# STM32G431 register map
File version: 2.8
CPU: CM4 r0p1, little endian, MPU, FPU, 4 interrupt priority bits
Registers are 32-bit, read-write, reset 0x0 unless marked. A register's access mark holds for its fields unless they carry their own. Offsets are from the block's base; [hi:lo] are bit positions; lines under a group give offsets from that group; {n}, {i} and the like mark numbered series; 'fields as' and 'values as' point back to an identical list.

## DBGMCU — Debug support
Base 0xE0042000
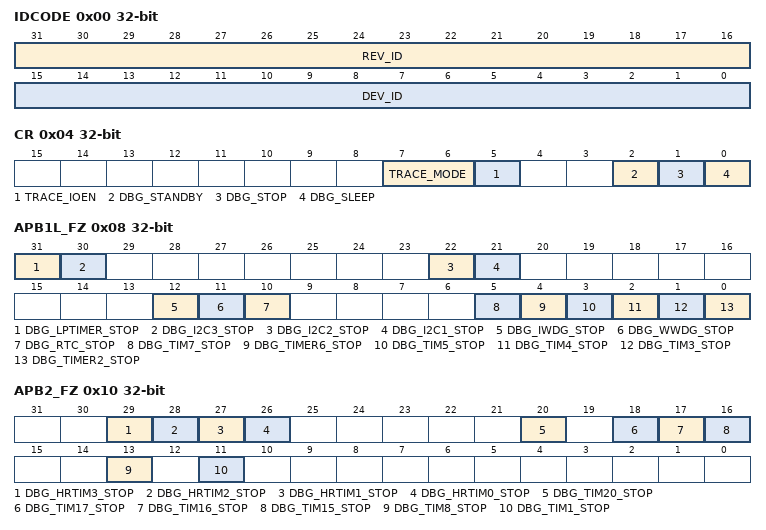
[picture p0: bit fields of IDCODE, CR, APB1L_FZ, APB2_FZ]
0x00 IDCODE ro — MCU Device ID Code Register
  [31:16] REV_ID — Revision Identifier
  [15:0] DEV_ID — Device Identifier
0x04 CR — Debug MCU Configuration Register
  [7:6] TRACE_MODE — Trace pin assignment control
  [5] TRACE_IOEN — Trace pin assignment control
  [2] DBG_STANDBY — Debug Standby Mode
  [1] DBG_STOP — Debug Stop Mode
  [0] DBG_SLEEP — Debug Sleep Mode
0x08 APB1L_FZ — APB Low Freeze Register 1
  [31] DBG_LPTIMER_STOP — LPTIM1 counter stopped when core is halted
  [30] DBG_I2C3_STOP — I2C3 SMBUS timeout mode stopped when core is halted
  [22] DBG_I2C2_STOP — I2C2 SMBUS timeout mode stopped when core is halted
  [21] DBG_I2C1_STOP — I2C1 SMBUS timeout mode stopped when core is halted
  [12] DBG_IWDG_STOP — Debug Independent Wachdog stopped when Core is halted
  [11] DBG_WWDG_STOP — Debug Window Wachdog stopped when Core is halted
  [10] DBG_RTC_STOP — Debug RTC stopped when Core is halted
  [5] DBG_TIM7_STOP — TIM7 counter stopped when core is halted
  [4] DBG_TIMER6_STOP — Debug Timer 6 stopped when Core is halted
  [3] DBG_TIM5_STOP — TIM5 counter stopped when core is halted
  [2] DBG_TIM4_STOP — TIM4 counter stopped when core is halted
  [1] DBG_TIM3_STOP — TIM3 counter stopped when core is halted
  [0] DBG_TIMER2_STOP — Debug Timer 2 stopped when Core is halted
0x0C APB1H_FZ — APB Low Freeze Register 2
  [1] DBG_I2C4_STOP
0x10 APB2_FZ — APB High Freeze Register
  [29] DBG_HRTIM3_STOP — DBG_HRTIM0_STOP
  [28] DBG_HRTIM2_STOP — DBG_HRTIM0_STOP
  [27] DBG_HRTIM1_STOP — DBG_HRTIM0_STOP
  [26] DBG_HRTIM0_STOP
  [20] DBG_TIM20_STOP — TIM20counter stopped when core is halted
  [18] DBG_TIM17_STOP — TIM17 counter stopped when core is halted
  [17] DBG_TIM16_STOP — TIM16 counter stopped when core is halted
  [16] DBG_TIM15_STOP — TIM15 counter stopped when core is halted
  [13] DBG_TIM8_STOP — TIM8 counter stopped when core is halted
  [11] DBG_TIM1_STOP — TIM1 counter stopped when core is halted

## DMA1 — DMA controller
Base 0x40020000
Same registers: DMA2 0x40020400
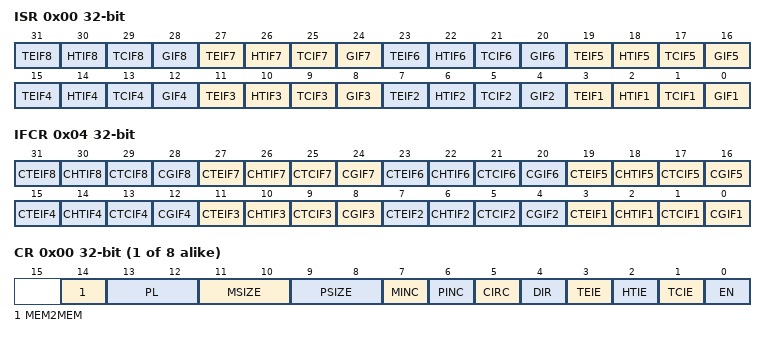
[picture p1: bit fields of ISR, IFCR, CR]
0x00 ISR ro — interrupt status register
  [4n-1] TEIF{n} (n=1..8) — Channel {n} Transfer Error flag
    0=NoError (No transfer error); 1=Error (A transfer error has occured)
  [4n-2] HTIF{n} (n=1..8) — Channel {n} Half Transfer Complete flag
    0=NotHalf (No half transfer event); 1=Half (A half transfer event has occured)
  [4n-3] TCIF{n} (n=1..8) — Channel {n} Transfer Complete flag
    0=NotComplete (No transfer complete event); 1=Complete (A transfer complete event has occured)
  [4n-4] GIF{n} (n=1..8) — Channel {n} Global interrupt flag
    0=NoEvent (No transfer error, half event, complete event); 1=Event (A transfer error, half event or complete event has occured)
0x04 IFCR wo — DMA interrupt flag clear register
  [4n-1] CTEIF{n} (n=1..8) — Channel {n} Transfer Error clear
    1=Clears the TEIF flag in the ISR register
  [4n-2] CHTIF{n} (n=1..8) — Channel {n} Half Transfer clear
    1=Clears the HTIF flag in the ISR register
  [4n-3] CTCIF{n} (n=1..8) — Channel {n} Transfer Complete clear
    1=Clears the TCIF flag in the ISR register
  [4n-4] CGIF{n} (n=1..8) — Channel {n} Global interrupt clear
    1=Clears the GIF, TEIF, HTIF, TCIF flags in the ISR register
0x08 CH{i} (i=1..8; step 0x14) group — Channel cluster: CCR?, CNDTR?, CPAR?, and CMAR? registers
  0x00 CR — DMA channel 1 configuration register
    [14] MEM2MEM
      0=Disabled (Memory to memory mode disabled); 1=Enabled (Memory to memory mode enabled)
    [13:12] PL
      0=Low (Low priority); 1=Medium priority; 2=High priority; 3=Very high priority
    [11:10] MSIZE
      0=Bits8 (8-bit size); 1=Bits16 (16-bit size); 2=Bits32 (32-bit size)
    [9:8] PSIZE
      values as MSIZE
    [7] MINC
      0=Disabled (Increment mode disabled); 1=Enabled (Increment mode enabled)
    [6] PINC
      values as MINC
    [5] CIRC
      0=Disabled (Circular buffer disabled); 1=Enabled (Circular buffer enabled)
    [4] DIR
      0=FromPeripheral (Read from peripheral); 1=FromMemory (Read from memory)
    [3] TEIE
      0=Disabled (Transfer Error interrupt disabled); 1=Enabled (Transfer Error interrupt enabled)
    [2] HTIE
      0=Disabled (Half Transfer interrupt disabled); 1=Enabled (Half Transfer interrupt enabled)
    [1] TCIE
      0=Disabled (Transfer Complete interrupt disabled); 1=Enabled (Transfer Complete interrupt enabled)
    [0] EN — channel enable
      0=Disabled (Channel disabled); 1=Enabled (Channel enabled)
  0x04 NDTR — channel x number of data to transfer register
    [15:0] NDT — Number of data items to transfer
  0x08 PAR — DMA channel x peripheral address register
    [31:0] PA — Peripheral address
  0x0C MAR — DMA channel x memory address register
    [31:0] MA — Memory 1 address (used in case of Double buffer mode)
